# daric register map
Vendor: cramium
Registers are 32-bit, read-write, reset 0x0 unless marked. A register's access mark holds for its fields unless they carry their own. Offsets are from the block's base; [hi:lo] are bit positions; {n}, {i} and the like mark numbered series.

## UDMA_SPIS_0
Base 0x50112000
Same registers: UDMA_SPIS_1 0x50113000
0x00 REG_RX_SADDR — See file:///F:/code/cram-nto/modules/ifsub/rtl/udma_spis_reg.sv
  [11:0] r_rx_startaddr
0x04 REG_RX_SIZE — See file:///F:/code/cram-nto/modules/ifsub/rtl/udma_spis_reg.sv
  [15:0] r_rx_size
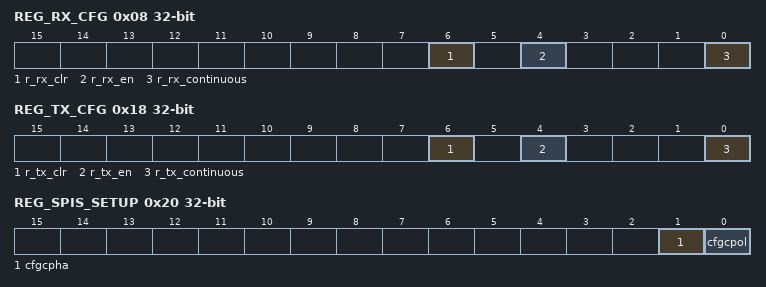
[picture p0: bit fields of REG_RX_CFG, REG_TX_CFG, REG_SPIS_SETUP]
0x08 REG_RX_CFG — See file:///F:/code/cram-nto/modules/ifsub/rtl/udma_spis_reg.sv
  [6] r_rx_clr, [4] r_rx_en, [0] r_rx_continuous
0x10 REG_TX_SADDR — See file:///F:/code/cram-nto/modules/ifsub/rtl/udma_spis_reg.sv
  [11:0] r_tx_startaddr
0x14 REG_TX_SIZE — See file:///F:/code/cram-nto/modules/ifsub/rtl/udma_spis_reg.sv
  [15:0] r_tx_size
0x18 REG_TX_CFG — See file:///F:/code/cram-nto/modules/ifsub/rtl/udma_spis_reg.sv
  [6] r_tx_clr, [4] r_tx_en, [0] r_tx_continuous
0x20 REG_SPIS_SETUP — See file:///F:/code/cram-nto/modules/ifsub/rtl/udma_spis_reg.sv
  [1] cfgcpha, [0] cfgcpol
0x24 REG_SEOT_CNT — See file:///F:/code/cram-nto/modules/ifsub/rtl/udma_spis_reg.sv
  [15:0] sr_seot_cnt
0x28 REG_SPIS_IRQ_EN — See file:///F:/code/cram-nto/modules/ifsub/rtl/udma_spis_reg.sv
  [0] seot_irq_en
0x2C REG_SPIS_RXCNT — See file:///F:/code/cram-nto/modules/ifsub/rtl/udma_spis_reg.sv
  [15:0] cfgrxcnt
0x30 REG_SPIS_TXCNT — See file:///F:/code/cram-nto/modules/ifsub/rtl/udma_spis_reg.sv
  [15:0] cfgtxcnt
0x34 REG_SPIS_DMCNT — See file:///F:/code/cram-nto/modules/ifsub/rtl/udma_spis_reg.sv
  [15:0] cfgdmcnt

## UDMA_ADC
Base 0x50114000
0x00 REG_RX_SADDR — See file:///F:/code/cram-nto/modules/ifsub/rtl/udma_adc_ts_reg_if.sv
  [11:0] r_rx_startaddr
0x04 REG_RX_SIZE — See file:///F:/code/cram-nto/modules/ifsub/rtl/udma_adc_ts_reg_if.sv
  [15:0] r_rx_size
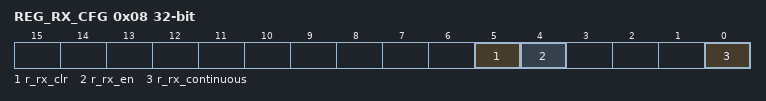
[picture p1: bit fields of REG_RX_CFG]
0x08 REG_RX_CFG — See file:///F:/code/cram-nto/modules/ifsub/rtl/udma_adc_ts_reg_if.sv
  [5] r_rx_clr, [4] r_rx_en, [0] r_rx_continuous
0x10 REG_CR_ADC — See file:///F:/code/cram-nto/modules/ifsub/rtl/udma_adc_ts_reg_if.sv
  [27:0] cr_adc

## BIO_FIFO0
Base 0x50129000
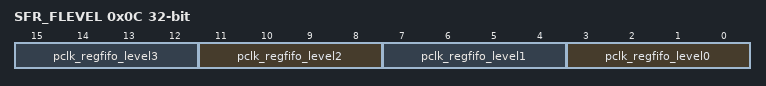
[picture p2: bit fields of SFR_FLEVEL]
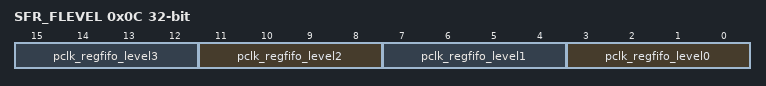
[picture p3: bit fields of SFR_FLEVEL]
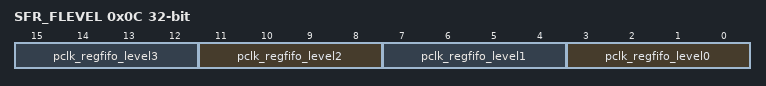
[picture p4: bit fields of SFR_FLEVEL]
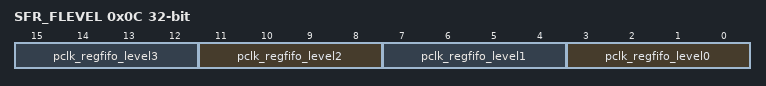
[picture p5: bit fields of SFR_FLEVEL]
0x0C SFR_FLEVEL — See file:///F:/code/cram-nto/modules/bio_bdma/rtl/bio_bdma.sv
  [4n+3:4n] pclk_regfifo_level{n} (n=0..3) — pclk_regfifo_level[{n}] read only status register
0x10 SFR_TXF0 — See file:///F:/code/cram-nto/modules/bio_bdma/rtl/bio_bdma.sv
  [31:0] fdin — fdin read/write control register
0x20 SFR_RXF0 — See file:///F:/code/cram-nto/modules/bio_bdma/rtl/bio_bdma.sv
  [31:0] fdout — fdout read only status register
0x38 SFR_EVENT_SET — See file:///F:/code/cram-nto/modules/bio_bdma/rtl/bio_bdma.sv
  [23:0] sfr_event_set — sfr_event_set read/write control register
0x3C SFR_EVENT_CLR — See file:///F:/code/cram-nto/modules/bio_bdma/rtl/bio_bdma.sv
  [23:0] sfr_event_clr — sfr_event_clr read/write control register
0x40 SFR_EVENT_STATUS — See file:///F:/code/cram-nto/modules/bio_bdma/rtl/bio_bdma.sv
  [31:0] sfr_event_status — sfr_event_status read only status register

## BIO_FIFO1
Base 0x5012A000
0x0C SFR_FLEVEL — See file:///F:/code/cram-nto/modules/bio_bdma/rtl/bio_bdma.sv
  [4n+3:4n] pclk_regfifo_level{n} (n=0..3) — pclk_regfifo_level[{n}] read only status register
0x14 SFR_TXF1 — See file:///F:/code/cram-nto/modules/bio_bdma/rtl/bio_bdma.sv
  [31:0] fdin — fdin read/write control register
0x24 SFR_RXF1 — See file:///F:/code/cram-nto/modules/bio_bdma/rtl/bio_bdma.sv
  [31:0] fdout — fdout read only status register
0x38 SFR_EVENT_SET — See file:///F:/code/cram-nto/modules/bio_bdma/rtl/bio_bdma.sv
  [23:0] sfr_event_set — sfr_event_set read/write control register
0x3C SFR_EVENT_CLR — See file:///F:/code/cram-nto/modules/bio_bdma/rtl/bio_bdma.sv
  [23:0] sfr_event_clr — sfr_event_clr read/write control register
0x40 SFR_EVENT_STATUS — See file:///F:/code/cram-nto/modules/bio_bdma/rtl/bio_bdma.sv
  [31:0] sfr_event_status — sfr_event_status read only status register

## BIO_FIFO2
Base 0x5012B000
0x0C SFR_FLEVEL — See file:///F:/code/cram-nto/modules/bio_bdma/rtl/bio_bdma.sv
  [4n+3:4n] pclk_regfifo_level{n} (n=0..3) — pclk_regfifo_level[{n}] read only status register
0x18 SFR_TXF2 — See file:///F:/code/cram-nto/modules/bio_bdma/rtl/bio_bdma.sv
  [31:0] fdin — fdin read/write control register
0x28 SFR_RXF2 — See file:///F:/code/cram-nto/modules/bio_bdma/rtl/bio_bdma.sv
  [31:0] fdout — fdout read only status register
0x38 SFR_EVENT_SET — See file:///F:/code/cram-nto/modules/bio_bdma/rtl/bio_bdma.sv
  [23:0] sfr_event_set — sfr_event_set read/write control register
0x3C SFR_EVENT_CLR — See file:///F:/code/cram-nto/modules/bio_bdma/rtl/bio_bdma.sv
  [23:0] sfr_event_clr — sfr_event_clr read/write control register
0x40 SFR_EVENT_STATUS — See file:///F:/code/cram-nto/modules/bio_bdma/rtl/bio_bdma.sv
  [31:0] sfr_event_status — sfr_event_status read only status register

## BIO_FIFO3
Base 0x5012C000
0x0C SFR_FLEVEL — See file:///F:/code/cram-nto/modules/bio_bdma/rtl/bio_bdma.sv
  [4n+3:4n] pclk_regfifo_level{n} (n=0..3) — pclk_regfifo_level[{n}] read only status register
0x1C SFR_TXF3 — See file:///F:/code/cram-nto/modules/bio_bdma/rtl/bio_bdma.sv
  [31:0] fdin — fdin read/write control register
0x2C SFR_RXF3 — See file:///F:/code/cram-nto/modules/bio_bdma/rtl/bio_bdma.sv
  [31:0] fdout — fdout read only status register
0x38 SFR_EVENT_SET — See file:///F:/code/cram-nto/modules/bio_bdma/rtl/bio_bdma.sv
  [23:0] sfr_event_set — sfr_event_set read/write control register
0x3C SFR_EVENT_CLR — See file:///F:/code/cram-nto/modules/bio_bdma/rtl/bio_bdma.sv
  [23:0] sfr_event_clr — sfr_event_clr read/write control register
0x40 SFR_EVENT_STATUS — See file:///F:/code/cram-nto/modules/bio_bdma/rtl/bio_bdma.sv
  [31:0] sfr_event_status — sfr_event_status read only status register
